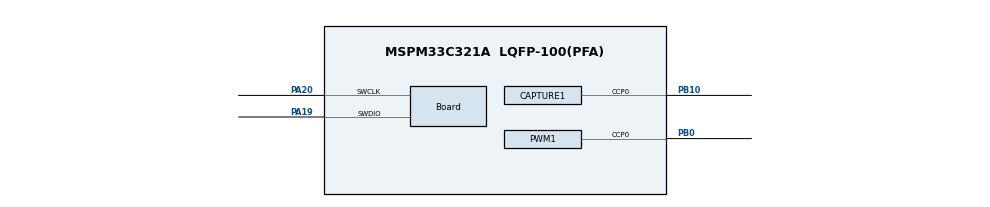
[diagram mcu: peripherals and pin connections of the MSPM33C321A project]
//@cliArgs --device "MSPM33C321A" --package "LQFP-100(PFA)" --part "Default"
//@v2CliArgs --device "MSPM33C321A" --package "LQFP-100(PFA)"
// @cliArgs --board /ti/boards/LP_MSPM33C321A --rtos nortos

/**
 * Import the modules used in this configuration.
 */
const CAPTURE       = scripting.addModule("/ti/driverlib/CAPTURE", {}, false);
const CAPTURE1      = CAPTURE.addInstance();
const PWM           = scripting.addModule("/ti/driverlib/PWM", {}, false);
const PWM1          = PWM.addInstance();
const SYSCTL        = scripting.addModule("/ti/driverlib/SYSCTL");
const ProjectConfig = scripting.addModule("/ti/project_config/ProjectConfig");

/**
 * Write custom configuration values to the imported modules.
 */
CAPTURE1.$name                      = "CAPTURE_0";
CAPTURE1.captMode                   = "COMBINED";
CAPTURE1.timerClkPrescale           = 256;
CAPTURE1.timerPeriod                = "524.29 ms";
CAPTURE1.interrupts                 = ["CC1_DN","ZERO"];
CAPTURE1.peripheral.$assign         = "TIMG4_0";
CAPTURE1.peripheral.ccp0Pin.$assign = "PB10";
CAPTURE1.ccp0PinConfig.$name        = "ti_driverlib_gpio_GPIOPinGeneric0";

const Board                       = scripting.addModule("/ti/driverlib/Board", {}, false);
Board.peripheral.$assign          = "DEBUGSS";
Board.peripheral.swclkPin.$assign = "PA20";
Board.peripheral.swdioPin.$assign = "PA19";

PWM1.$name                      = "PWM_0";
PWM1.ccIndex                    = [0];
PWM1.clockPrescale              = 256;
PWM1.PWM_CHANNEL_0.$name        = "ti_driverlib_pwm_PWMTimerCC0";
PWM1.PWM_CHANNEL_0.dutyCycle    = 50;
PWM1.ccp0PinConfig.$name        = "ti_driverlib_gpio_GPIOPinGeneric1";
PWM1.peripheral.$assign         = "TIMG4_1";
PWM1.peripheral.ccp0Pin.$assign = "PB0";

SYSCTL.forceDefaultClkConfig = true;
SYSCTL.peripheral.$assign    = "SYSCTL";

ProjectConfig.migrationCondition = true;
ProjectConfig.genLinker          = true;
ProjectConfig.genStartup         = true;
ProjectConfig.genLibs            = true;
ProjectConfig.genOpts            = true;
